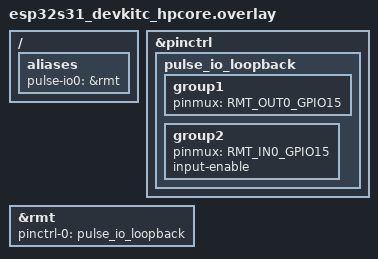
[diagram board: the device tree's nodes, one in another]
/*
 * Copyright (c) 2026 Espressif Systems (Shanghai) Co., Ltd.
 *
 * SPDX-License-Identifier: Apache-2.0
 */

&pinctrl {
	pulse_io_loopback: pulse_io_loopback {
		group1 {
			pinmux = <RMT_OUT0_GPIO15>;
		};

		group2 {
			pinmux = <RMT_IN0_GPIO15>;
			input-enable;
		};
	};
};

&rmt {
	pinctrl-0 = <&pulse_io_loopback>;
	pinctrl-names = "default";
	status = "okay";
};

/ {
	aliases {
		pulse-io0 = &rmt;
	};
};
